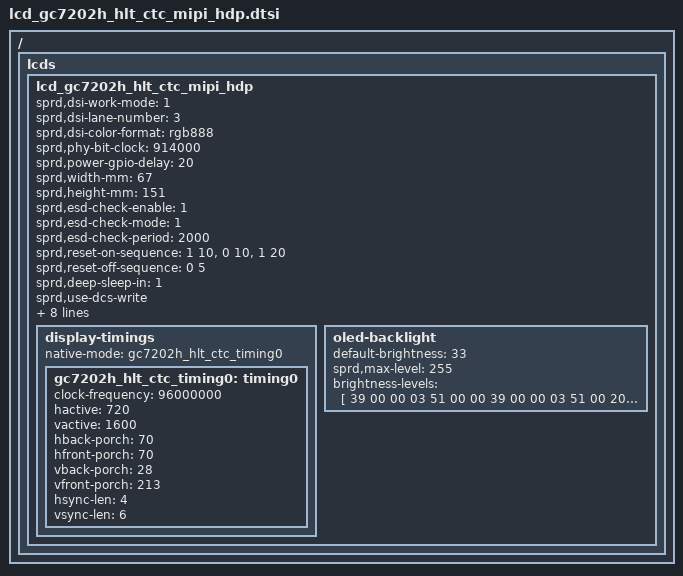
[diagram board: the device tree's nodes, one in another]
/*
 * gc7202h  LCD config dtsi file for spreadtrum
 *
 * Copyright (C) 2018, Spreadtrum Communications Inc.
 *
 * SPDX-License-Identifier: (GPL-2.0+ OR MIT)
 */

/ {
    fragment {
        target-path = "/";
        __overlay__ {
            lcds {
                lcd_gc7202h_hlt_ctc_mipi_hdp: lcd_gc7202h_hlt_ctc_mipi_hdp {
                    sprd,dsi-work-mode = <1>; /* video burst mode*/
                    sprd,dsi-lane-number = <3>;
                    sprd,dsi-color-format = "rgb888";

                    sprd,phy-bit-clock = <914000>; /* kbps */
                    //sprd,phy-escape-clock = <20000>;/* kHz */
                    //sprd,dpi-clk-div = <1>;
                    sprd,power-gpio-delay = <20>;/* ms */

                    sprd,width-mm = <67>;
                    sprd,height-mm = <151>;

                    sprd,esd-check-enable = <1>;
                    sprd,esd-check-mode = <1>;
                    sprd,esd-check-period = <2000>;

                    sprd,reset-on-sequence = <1 10>, <0 10>, <1 20>;
                    sprd,reset-off-sequence = <0 5>;

                    sprd,deep-sleep-in = <1>;
                    sprd,use-dcs-write;
                    sprd,initial-command = [
                        39 00 00 04 FF 55 AA 66
                        39 00 00 02 FF B3
                        39 00 00 02 2B 0C
                        39 00 00 02 29 3F
                        39 00 00 02 28 C0
                        39 00 00 02 2A 03
                        39 00 00 02 68 0F
                        39 00 00 02 FF 20
                        39 00 00 02 FB 00
                        39 00 00 02 FF 21
                        39 00 00 02 FB 00
                        39 00 00 02 FF 22
                        39 00 00 02 FB 00
                        39 00 00 02 FF 23
                        39 00 00 02 FB 00
                        39 00 00 02 FF 24
                        39 00 00 02 FB 00
                        39 00 00 02 FF 27
                        39 00 00 02 FB 00
                        39 00 00 02 FF 28
                        39 00 00 02 FB 00
                        39 00 00 02 FF B3
                        39 00 00 02 FB 00
                        39 00 00 02 FF 10
                        39 00 00 02 FB 00
                        39 00 00 02 FF 28
                        39 00 00 02 53 44
                        39 00 00 02 50 4C
                        39 00 00 02 52 52
                        39 00 00 02 4D A1
                        39 00 00 02 FF 20
                        39 00 00 02 A5 00
                        39 00 00 02 A6 FF
                        39 00 00 02 A9 00
                        39 00 00 02 AA FF
                        39 00 00 02 D3 06
                        39 00 00 02 2D 1F
                        39 00 00 02 2E 42
                        39 00 00 02 2F 14
                        39 00 00 02 FF 22
                        39 00 00 02 1F 06
                        39 00 00 02 FF B3
                        39 00 00 02 3E 03
                        39 00 00 02 58 84
                        39 00 00 02 53 1A
                        39 00 00 02 82 1A
                        39 00 00 02 4A 0F
                        39 00 00 02 7D 80
                        39 00 00 02 5B 4B
                        39 00 00 02 48 26
                        39 00 00 02 7C 8C
                        39 00 00 02 FF 20
                        39 00 00 02 A3 47
                        39 00 00 02 A7 47
                        39 00 00 02 FF B3
                        39 00 00 02 3F 37
                        39 00 00 02 5E 10
                        39 00 00 02 FF 22
                        39 00 00 02 E4 01
                        39 00 00 02 01 06
                        39 00 00 02 02 40
                        39 00 00 02 25 08
                        39 00 00 02 26 00
                        39 00 00 02 2E DA
                        39 00 00 02 2F 00
                        39 00 00 02 36 0A
                        39 00 00 02 37 00
                        39 00 00 02 3F DA
                        39 00 00 02 40 00
                        39 00 00 02 FF 28
                        39 00 00 02 01 25
                        39 00 00 02 02 25
                        39 00 00 02 03 23
                        39 00 00 02 04 23
                        39 00 00 02 05 1B
                        39 00 00 02 06 03
                        39 00 00 02 07 18
                        39 00 00 02 08 19
                        39 00 00 02 09 1A
                        39 00 00 02 0A 09
                        39 00 00 02 0B 0B
                        39 00 00 02 0C 0D
                        39 00 00 02 0D 0F
                        39 00 00 02 0E 01
                        39 00 00 02 0F 25
                        39 00 00 02 10 25
                        39 00 00 02 11 25
                        39 00 00 02 12 25
                        39 00 00 02 13 25
                        39 00 00 02 14 25
                        39 00 00 02 15 25
                        39 00 00 02 16 25
                        39 00 00 02 17 23
                        39 00 00 02 18 23
                        39 00 00 02 19 23
                        39 00 00 02 1A 23
                        39 00 00 02 1B 1B
                        39 00 00 02 1C 02
                        39 00 00 02 1D 18
                        39 00 00 02 1E 19
                        39 00 00 02 1F 1A
                        39 00 00 02 20 08
                        39 00 00 02 21 0A
                        39 00 00 02 22 0C
                        39 00 00 02 23 0E
                        39 00 00 02 24 00
                        39 00 00 02 25 25
                        39 00 00 02 26 25
                        39 00 00 02 27 25
                        39 00 00 02 28 25
                        39 00 00 02 29 25
                        39 00 00 02 2A 25
                        39 00 00 02 2B 25
                        39 00 00 02 2D 25
                        39 00 00 02 30 00
                        39 00 00 02 31 00
                        39 00 00 02 34 00
                        39 00 00 02 35 00
                        39 00 00 02 36 00
                        39 00 00 02 37 00
                        39 00 00 02 38 00
                        39 00 00 02 39 00
                        39 00 00 02 2F 03
                        39 00 00 02 FF 21
                        39 00 00 02 7E 03
                        39 00 00 02 7F 23
                        39 00 00 02 8B 23
                        39 00 00 02 80 07
                        39 00 00 02 8C 03
                        39 00 00 02 81 03
                        39 00 00 02 8D 07
                        39 00 00 02 AF 40
                        39 00 00 02 B0 40
                        39 00 00 02 83 02
                        39 00 00 02 8F 02
                        39 00 00 02 84 48
                        39 00 00 02 90 48
                        39 00 00 02 85 6D
                        39 00 00 02 91 6D
                        39 00 00 02 87 02
                        39 00 00 02 93 06
                        39 00 00 02 82 B0
                        39 00 00 02 8E B0
                        39 00 00 02 2B 00
                        39 00 00 02 45 0F
                        39 00 00 02 46 B5
                        39 00 00 02 4C B5
                        39 00 00 02 52 B5
                        39 00 00 02 58 B5
                        39 00 00 02 47 0A
                        39 00 00 02 4D 09
                        39 00 00 02 53 23
                        39 00 00 02 59 24
                        39 00 00 02 48 23
                        39 00 00 02 4E 24
                        39 00 00 02 54 0A
                        39 00 00 02 5A 09
                        39 00 00 02 76 40
                        39 00 00 02 77 40
                        39 00 00 02 78 40
                        39 00 00 02 79 40
                        39 00 00 02 49 04
                        39 00 00 02 4A 7B
                        39 00 00 02 4F 04
                        39 00 00 02 50 7B
                        39 00 00 02 55 04
                        39 00 00 02 56 86
                        39 00 00 02 5B 04
                        39 00 00 02 5C 86
                        39 00 00 02 BE 03
                        39 00 00 02 C0 74
                        39 00 00 02 C1 70
                        39 00 00 02 BF BB
                        39 00 00 02 C2 8B
                        39 00 00 02 C3 8B
                        39 00 00 02 C6 72
                        39 00 00 02 C7 54
                        39 00 00 02 29 00
                        39 00 00 02 FF 22
                        39 00 00 02 05 10
                        39 00 00 02 08 10
                        39 00 00 02 FF 20
                        39 00 00 02 25 12
                        39 00 00 02 C3 00
                        39 00 00 02 C4 9B
                        39 00 00 02 C5 00
                        39 00 00 02 C6 9B
                        39 00 00 02 B3 00
                        39 00 00 02 B4 22
                        39 00 00 02 B5 00
                        39 00 00 02 B6 DC
                        39 00 00 02 FF 28
                        39 00 00 02 3D 3D
                        39 00 00 02 3E 3D
                        39 00 00 02 3F 4F
                        39 00 00 02 40 4F
                        39 00 00 02 45 3C
                        39 00 00 02 46 3C
                        39 00 00 02 47 4E
                        39 00 00 02 48 4E
                        39 00 00 02 5A 92
                        39 00 00 02 5B 8B
                        39 00 00 02 FF 20
                        39 00 00 02 7E 01
                        39 00 00 02 7F 00
                        39 00 00 02 80 04
                        39 00 00 02 81 00
                        39 00 00 02 82 00
                        39 00 00 02 83 64
                        39 00 00 02 84 64
                        39 00 00 02 85 3E
                        39 00 00 02 86 09
                        39 00 00 02 87 3E
                        39 00 00 02 88 09
                        39 00 00 02 8A 0A
                        39 00 00 02 8B 0A
                        39 00 00 02 FF 23
                        39 00 00 02 29 03
                        39 00 00 11 01 00 03 00 10 00 43 00 5E 00 76 00 88 00 99 00 A7
                        39 00 00 11 02 00 B7 00 E1 01 04 01 3A 01 64 01 A4 01 DE 01 E0
                        39 00 00 11 03 02 1E 02 6A 02 9B 02 DB 03 04 03 3B 03 4C 03 63
                        39 00 00 0D 04 03 73 03 8E 03 A2 03 c2 03 E8 03 FF
                        39 00 00 11 0D 00 03 00 10 00 43 00 5E 00 76 00 88 00 99 00 A7
                        39 00 00 11 0E 00 B7 00 E1 01 04 01 3A 01 64 01 A4 01 DE 01 E0
                        39 00 00 11 0F 02 1E 02 6A 02 9B 02 DB 03 04 03 3b 03 4c 03 63
                        39 00 00 0D 10 03 73 03 8E 03 A2 03 c2 03 E8 03 FF
                        39 00 00 02 2B 01
                        39 00 00 02 2D 65
                        39 00 00 02 37 01
                        39 00 00 02 2E 00
                        39 00 00 02 32 02
                        39 00 00 02 33 16
                        39 00 00 02 B9 31
                        39 00 00 02 B8 B7
                        39 00 00 02 35 CC
                        39 00 00 02 36 0C
                        39 00 00 02 30 00
                        39 00 00 0D 1F D8 D8 D8 D8 D8 D8 D8 D8 D8 D8 D8 FF
                        39 00 00 0D 20 00 00 00 00 00 00 00 00 00 00 00 00
                        39 00 00 0D 21 D8 D8 D8 D8 D8 D8 D8 D8 D8 D8 D8 FF
                        39 00 00 0D 22 00 00 00 00 00 00 00 00 00 00 00 00
                        39 00 00 0D 23 D8 D8 D8 D8 D8 D8 D8 D8 D8 D8 D8 FF
                        39 00 00 0D 24 00 00 00 00 00 00 00 00 00 00 00 00
                        39 00 00 0D 25 10 24 38 4C 60 74 88 9C B0 C4 F0 FF
                        39 00 00 02 FF 22
                        39 00 00 02 EF 06
                        39 00 00 02 FF 10
                        39 00 00 02 36 08
                        39 00 00 02 35 00
                        39 00 00 02 53 2C
                        39 00 00 03 51 00 00
                        39 00 00 02 55 00
                        39 00 00 02 69 00
                        39 00 00 02 BA 02
                        39 00 00 02 FF 24
                        39 00 00 02 7D 55
                        39 00 00 04 FF 66 99 55
                        39 00 00 02 FF 10
                        39 78 00 02 11 00
                        39 14 00 02 29 00
                    ];

                    sprd,sleep-in-command = [
                            39 00 00 04 FF 55 AA 66
                            39 00 00 02 FF B3
                            39 00 00 02 2B 00
                            39 00 00 02 29 00
                            39 00 00 02 28 00
                            39 00 00 02 2A 00
                            39 00 00 02 68 00
                            39 00 00 02 FF 20
                            39 00 00 02 4A 01
                            39 00 00 02 48 10
                            39 00 00 02 49 00
                            39 00 00 02 FF 10
                            23 00 00 02 28 00
                            23 64 00 02 10 00
                        ];

                    sprd,sleep-out-command = [
                            39 78 00 01 11
                            39 32 00 01 29
                        ];

                    sprd,deep-sleep-in-command = [
                            39 00 00 04 FF 55 AA 66
                            39 00 00 02 FF 20
                            39 00 00 02 4A 01
                            39 00 00 02 48 10
                            39 00 00 02 49 00
                            39 00 00 02 FF 10
                            23 32 00 02 28 00
                            23 78 00 02 10 00
                            39 00 00 02 4F 01
                        ];

                    display-timings {
                        native-mode = <&gc7202h_hlt_ctc_timing0>;

                        gc7202h_hlt_ctc_timing0: timing0 {
                            clock-frequency = <96000000>;
                            hactive = <720>;
                            vactive = <1600>;
                            hback-porch = <70>;
                            hfront-porch = <70>;
                            vback-porch = <28>;
                            vfront-porch = <213>;
                            hsync-len = <4>;
                            vsync-len = <6>;
                        };
                    };

                    oled-backlight {
                        default-brightness = <33>;
                        sprd,max-level = <255>;
                        brightness-levels = [
                            39 00 00 03 51 00 00
                            39 00 00 03 51 00 20
                            39 00 00 03 51 00 30
                            39 00 00 03 51 00 40
                            39 00 00 03 51 00 50
                            39 00 00 03 51 00 60
                            39 00 00 03 51 00 70
                            39 00 00 03 51 00 80
                            39 00 00 03 51 00 90
                            39 00 00 03 51 00 A0
                            39 00 00 03 51 00 B0
                            39 00 00 03 51 00 C0
                            39 00 00 03 51 00 D0
                            39 00 00 03 51 00 E0
                            39 00 00 03 51 00 F0
                            39 00 00 03 51 01 00
                            39 00 00 03 51 01 11
                            39 00 00 03 51 01 21
                            39 00 00 03 51 01 31
                            39 00 00 03 51 01 41
                            39 00 00 03 51 01 51
                            39 00 00 03 51 01 61
                            39 00 00 03 51 01 71
                            39 00 00 03 51 01 81
                            39 00 00 03 51 01 91
                            39 00 00 03 51 01 A1
                            39 00 00 03 51 01 B1
                            39 00 00 03 51 01 C1
                            39 00 00 03 51 01 D1
                            39 00 00 03 51 01 E1
                            39 00 00 03 51 01 F1
                            39 00 00 03 51 02 01
                            39 00 00 03 51 02 11
                            39 00 00 03 51 02 22
                            39 00 00 03 51 02 32
                            39 00 00 03 51 02 42
                            39 00 00 03 51 02 52
                            39 00 00 03 51 02 62
                            39 00 00 03 51 02 72
                            39 00 00 03 51 02 82
                            39 00 00 03 51 02 92
                            39 00 00 03 51 02 A2
                            39 00 00 03 51 02 B2
                            39 00 00 03 51 02 C2
                            39 00 00 03 51 02 D2
                            39 00 00 03 51 02 E2
                            39 00 00 03 51 02 F2
                            39 00 00 03 51 03 02
                            39 00 00 03 51 03 12
                            39 00 00 03 51 03 22
                            39 00 00 03 51 03 32
                            39 00 00 03 51 03 43
                            39 00 00 03 51 03 53
                            39 00 00 03 51 03 63
                            39 00 00 03 51 03 73
                            39 00 00 03 51 03 83
                            39 00 00 03 51 03 93
                            39 00 00 03 51 03 A3
                            39 00 00 03 51 03 B3
                            39 00 00 03 51 03 C3
                            39 00 00 03 51 03 D3
                            39 00 00 03 51 03 E3
                            39 00 00 03 51 03 F3
                            39 00 00 03 51 04 03
                            39 00 00 03 51 04 13
                            39 00 00 03 51 04 23
                            39 00 00 03 51 04 33
                            39 00 00 03 51 04 43
                            39 00 00 03 51 04 54
                            39 00 00 03 51 04 64
                            39 00 00 03 51 04 74
                            39 00 00 03 51 04 84
                            39 00 00 03 51 04 94
                            39 00 00 03 51 04 A4
                            39 00 00 03 51 04 B4
                            39 00 00 03 51 04 C4
                            39 00 00 03 51 04 D4
                            39 00 00 03 51 04 E4
                            39 00 00 03 51 04 F4
                            39 00 00 03 51 05 04
                            39 00 00 03 51 05 14
                            39 00 00 03 51 05 24
                            39 00 00 03 51 05 34
                            39 00 00 03 51 05 44
                            39 00 00 03 51 05 54
                            39 00 00 03 51 05 65
                            39 00 00 03 51 05 75
                            39 00 00 03 51 05 85
                            39 00 00 03 51 05 95
                            39 00 00 03 51 05 A5
                            39 00 00 03 51 05 B5
                            39 00 00 03 51 05 C5
                            39 00 00 03 51 05 D5
                            39 00 00 03 51 05 E5
                            39 00 00 03 51 05 F5
                            39 00 00 03 51 06 05
                            39 00 00 03 51 06 15
                            39 00 00 03 51 06 25
                            39 00 00 03 51 06 35
                            39 00 00 03 51 06 45
                            39 00 00 03 51 06 55
                            39 00 00 03 51 06 65
                            39 00 00 03 51 06 76
                            39 00 00 03 51 06 86
                            39 00 00 03 51 06 96
                            39 00 00 03 51 06 A6
                            39 00 00 03 51 06 B6
                            39 00 00 03 51 06 C6
                            39 00 00 03 51 06 D6
                            39 00 00 03 51 06 E6
                            39 00 00 03 51 06 F6
                            39 00 00 03 51 07 06
                            39 00 00 03 51 07 16
                            39 00 00 03 51 07 26
                            39 00 00 03 51 07 36
                            39 00 00 03 51 07 46
                            39 00 00 03 51 07 56
                            39 00 00 03 51 07 66
                            39 00 00 03 51 07 76
                            39 00 00 03 51 07 87
                            39 00 00 03 51 07 97
                            39 00 00 03 51 07 A7
                            39 00 00 03 51 07 B7
                            39 00 00 03 51 07 C7
                            39 00 00 03 51 07 D7
                            39 00 00 03 51 07 E7
                            39 00 00 03 51 07 F7
                            39 00 00 03 51 08 07
                            39 00 00 03 51 08 17
                            39 00 00 03 51 08 27
                            39 00 00 03 51 08 37
                            39 00 00 03 51 08 47
                            39 00 00 03 51 08 57
                            39 00 00 03 51 08 67
                            39 00 00 03 51 08 77
                            39 00 00 03 51 08 87
                            39 00 00 03 51 08 98
                            39 00 00 03 51 08 A8
                            39 00 00 03 51 08 B8
                            39 00 00 03 51 08 C8
                            39 00 00 03 51 08 D8
                            39 00 00 03 51 08 E8
                            39 00 00 03 51 08 F8
                            39 00 00 03 51 09 08
                            39 00 00 03 51 09 18
                            39 00 00 03 51 09 28
                            39 00 00 03 51 09 38
                            39 00 00 03 51 09 48
                            39 00 00 03 51 09 58
                            39 00 00 03 51 09 68
                            39 00 00 03 51 09 78
                            39 00 00 03 51 09 88
                            39 00 00 03 51 09 98
                            39 00 00 03 51 09 A9
                            39 00 00 03 51 09 B9
                            39 00 00 03 51 09 C9
                            39 00 00 03 51 09 D9
                            39 00 00 03 51 09 E9
                            39 00 00 03 51 09 F9
                            39 00 00 03 51 0A 09
                            39 00 00 03 51 0A 19
                            39 00 00 03 51 0A 29
                            39 00 00 03 51 0A 39
                            39 00 00 03 51 0A 49
                            39 00 00 03 51 0A 59
                            39 00 00 03 51 0A 69
                            39 00 00 03 51 0A 79
                            39 00 00 03 51 0A 89
                            39 00 00 03 51 0A 99
                            39 00 00 03 51 0A A9
                            39 00 00 03 51 0A BA
                            39 00 00 03 51 0A CA
                            39 00 00 03 51 0A DA
                            39 00 00 03 51 0A EA
                            39 00 00 03 51 0A FA
                            39 00 00 03 51 0B 0A
                            39 00 00 03 51 0B 1A
                            39 00 00 03 51 0B 2A
                            39 00 00 03 51 0B 3A
                            39 00 00 03 51 0B 4A
                            39 00 00 03 51 0B 5A
                            39 00 00 03 51 0B 6A
                            39 00 00 03 51 0B 7A
                            39 00 00 03 51 0B 8A
                            39 00 00 03 51 0B 9A
                            39 00 00 03 51 0B AA
                            39 00 00 03 51 0B BA
                            39 00 00 03 51 0B CB
                            39 00 00 03 51 0B DB
                            39 00 00 03 51 0B EB
                            39 00 00 03 51 0B FB
                            39 00 00 03 51 0C 0B
                            39 00 00 03 51 0C 1B
                            39 00 00 03 51 0C 2B
                            39 00 00 03 51 0C 3B
                            39 00 00 03 51 0C 4B
                            39 00 00 03 51 0C 5B
                            39 00 00 03 51 0C 6B
                            39 00 00 03 51 0C 7B
                            39 00 00 03 51 0C 8B
                            39 00 00 03 51 0C 9B
                            39 00 00 03 51 0C AB
                            39 00 00 03 51 0C BB
                            39 00 00 03 51 0C CB
                            39 00 00 03 51 0C DC
                            39 00 00 03 51 0C EC
                            39 00 00 03 51 0C FC
                            39 00 00 03 51 0D 0C
                            39 00 00 03 51 0D 1C
                            39 00 00 03 51 0D 2C
                            39 00 00 03 51 0D 3C
                            39 00 00 03 51 0D 4C
                            39 00 00 03 51 0D 5C
                            39 00 00 03 51 0D 6C
                            39 00 00 03 51 0D 7C
                            39 00 00 03 51 0D 8C
                            39 00 00 03 51 0D 9C
                            39 00 00 03 51 0D AC
                            39 00 00 03 51 0D BC
                            39 00 00 03 51 0D CC
                            39 00 00 03 51 0D DC
                            39 00 00 03 51 0D ED
                            39 00 00 03 51 0D FD
                            39 00 00 03 51 0E 0D
                            39 00 00 03 51 0E 1D
                            39 00 00 03 51 0E 2D
                            39 00 00 03 51 0E 3D
                            39 00 00 03 51 0E 4D
                            39 00 00 03 51 0E 5D
                            39 00 00 03 51 0E 6D
                            39 00 00 03 51 0E 7D
                            39 00 00 03 51 0E 8D
                            39 00 00 03 51 0E 9D
                            39 00 00 03 51 0E AD
                            39 00 00 03 51 0E BD
                            39 00 00 03 51 0E CD
                            39 00 00 03 51 0E DD
                            39 00 00 03 51 0E ED
                            39 00 00 03 51 0E FE
                            39 00 00 03 51 0F 0E
                            39 00 00 03 51 0F 1E
                            39 00 00 03 51 0F 2E
                            39 00 00 03 51 0F 3E
                            39 00 00 03 51 0F 4E
                            39 00 00 03 51 0F 5E
                            39 00 00 03 51 0F 6E
                            39 00 00 03 51 0F 7E
                            39 00 00 03 51 0F 8E
                            39 00 00 03 51 0F 9E
                            39 00 00 03 51 0F AE
                            39 00 00 03 51 0F BE
                            39 00 00 03 51 0F CE
                            39 00 00 03 51 0F DE
                            39 00 00 03 51 0F EE
                            39 00 00 03 51 0F F6
                            39 00 00 03 51 0F F8
                        ];
                    };
                };
            };
        };
    };
};
